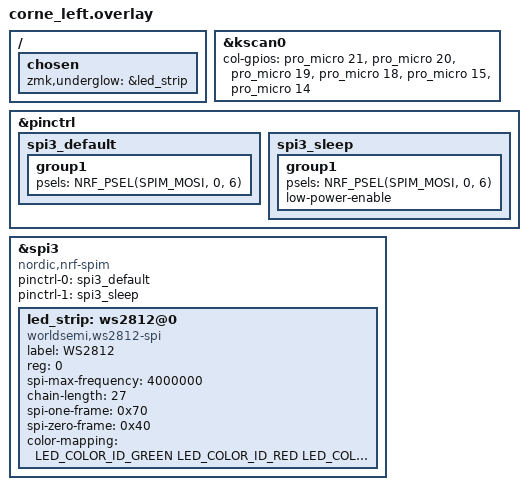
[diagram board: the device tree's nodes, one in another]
#include "corne.dtsi"
#include <dt-bindings/led/led.h>

&kscan0 {
    col-gpios =
        <&pro_micro 21 GPIO_ACTIVE_HIGH>,
        <&pro_micro 20 GPIO_ACTIVE_HIGH>,
        <&pro_micro 19 GPIO_ACTIVE_HIGH>,
        <&pro_micro 18 GPIO_ACTIVE_HIGH>,
        <&pro_micro 15 GPIO_ACTIVE_HIGH>,
        <&pro_micro 14 GPIO_ACTIVE_HIGH>;
};

/* Cấu hình chân P0.06 (D1) cho SPI */
&pinctrl {
    spi3_default: spi3_default {
        group1 {
            psels = <NRF_PSEL(SPIM_MOSI, 0, 6)>;
        };
    };

    spi3_sleep: spi3_sleep {
        group1 {
            psels = <NRF_PSEL(SPIM_MOSI, 0, 6)>;
            low-power-enable;
        };
    };
};

/* Kích hoạt module SPI3 điều khiển LED */
&spi3 {
    compatible = "nordic,nrf-spim";
    status = "okay";
    pinctrl-0 = <&spi3_default>;
    pinctrl-1 = <&spi3_sleep>;
    pinctrl-names = "default", "sleep";

    led_strip: ws2812@0 {
        compatible = "worldsemi,ws2812-spi";
        label = "WS2812";
        reg = <0>;
        spi-max-frequency = <4000000>;
        
        /* Tổng 27 LED (21 phím + 6 gầm) */
        chain-length = <27>;
        
        spi-one-frame = <0x70>;
        spi-zero-frame = <0x40>;
        color-mapping = <LED_COLOR_ID_GREEN LED_COLOR_ID_RED LED_COLOR_ID_BLUE>;
    };
};

/* Trỏ node underglow về led_strip mới */
/ {
    chosen {
        zmk,underglow = &led_strip;
    };
};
